# SAMA7D65D4GN8 register map
Vendor: Microchip Technology; Series: SAMA7D6; File version: 0
Registers are 32-bit, read-write, reset 0x0 unless marked. A register's access mark holds for its fields unless they carry their own. Offsets are from the block's base; [hi:lo] are bit positions; {n}, {i} and the like mark numbered series.

## SPDIFTX — Sony/Philips Digital Interface
Base 0xE2810000
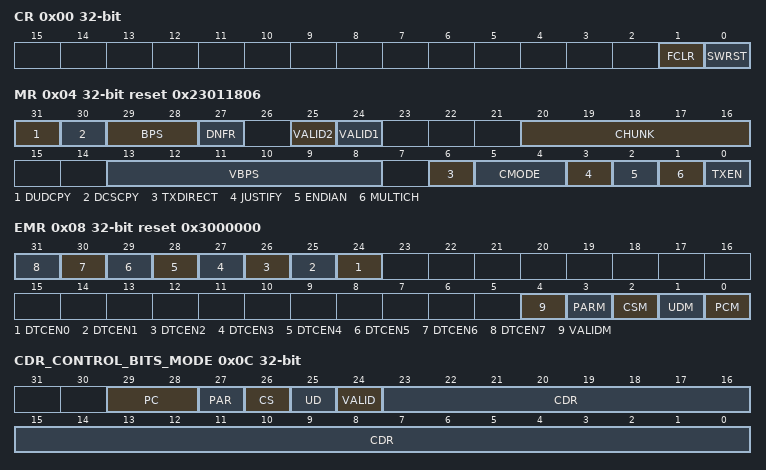
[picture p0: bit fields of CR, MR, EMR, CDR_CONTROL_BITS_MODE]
0x00 CR wo — SPDIF Transmitter Control Register
  [1] FCLR — FIFO clear
    0=No effect; 1=Empties Channel 1 and Channel 2 FIFOs
  [0] SWRST — Software Reset
    0=No effect; 1=Resets the SPDIFTX interface
0x04 MR reset 0x23011806 — SPDIF Transmitter Mode Register
  [31] DUDCPY — Disable User Data Copy
    0=Any data written in SPDDIFTX_CH1UDx registers is copied to SPDDIFTX_CH2UDx; 1=SPDDIFTX_CH1UDx and SPDDIFTX_CH2UDx are independent
  [30] DCSCPY — Disable Channel Status Copy
    0=Any data written in SPDDIFTX_CH1Sx registers is copied to SPDDIFTX_CH2Sx; 1=SPDDIFTX_CH1Sx and SPDDIFTX_CH2Sx are independent
  [29:28] BPS — Bytes Per Sample
    0=BYTE1 (SPDIFTX_CDR data holding operating mode is optimized for data size up to 8 bits.); 1=BYTE2 (SPDIFTX_CDR data holding operating mode is optimized for data size in range 9 to 16 bits.); 2=BYTE3 (SPDIFTX_CDR data holding operating mode is optimized for data size in range 17 to 24 bits.); 3=BYTE4 (SPDIFTX_CDR data holding operating mode is optimized for data size in range 25 to 32 bits.)
  [27] DNFR — Disable Null Frame on underrrun
    0=In case of Underrun (SPDIFTX_ISR.TXEMPTY flag is set and IP need a data) invalid frames are sent (validity bit at level '1'); 1=In case of Underrun (SPDIFTX_ISR.TXEMPTY flag is set and IP need a data) valid frames are sent
  [25] VALID2 — Validity Bit Channel 2
  [24] VALID1 — Validity Bit Channel 1
  [20:16] CHUNK — DMA Chunk Size
  [13:8] VBPS — Valid Bits Per Sample
  [6] TXDIRECT — Transmitter Direct Access Enable
    0=The SPDIFTX holding register must be written by software or DMA to transmit audio samples on the SPDIF line; 1=Asynchronous Sample Rate Converter (ASRC) can directly transfer the audio samples on the SPDIF line without software or DMA intervention
  [5:4] CMODE — Common Audio Register Transfer Mode (if BPS=2)
    0=CHANNEL_INDEX (SPDIFTX_CDR.CDR[25:24] indicates the channel on which the data CDR[23:0] will be transmitted (1 for channel 1, 2 for channel 2).Transmitted data are located on SPDIFTX_CDR.CDR[23:0].); 1=CHANNELS_TOGGLING (The data are stored alternately in the FIFO of channel 1 and channel 2. The first sent data after a software or hardware reset is stored in the FIFO of channel 1. Transmitted data are located on SPDIFTX_CDR.CDR[23:0].); 2=COMPACT_24BIT (This mode is optimized for 24-bit data compacted on 32-bit memory space. Transmitted data are located on SPDIFTX_CDR.CDR[31:0]. The 32 bits of SPDIFTX_CDR are used and contains one or more channel data.); 3=CONTROL_BITS (Control bits (preamble, validity, user data, channel status, parity) can be managed by writing SPDIFTX_CDR.CDR[31:24] depending on SPDIFTX_EMR configuration. The data are stored alternately in the FIFO of channel 1 and channel 2. The first data sent after a software or hardware reset is stored in the FIFO of channel 1. Transmitted data are located on SPDIFTX_CDR.CDR[23:0].)
  [3] JUSTIFY — Data Justification
    0=LSB (Least Significant Bit justification. The valid bits of the signal are aligned on the least-significant bits of the container.); 1=MSB (Most Significant Bit justification. The valid bits of the signal are aligned on the most-significant bits of the container.)
  [2] ENDIAN — Data Word Endian Mode
    0=LITTLE (Little-endian mode.); 1=BIG (Big-endian mode.)
  [1] MULTICH — Multichannel Transfer
    0=MONO (One channel is sent on channel 1 to SPDIFTX_TX and is copied on channel 2.); 1=DUAL (Two separate channels are sent to SPDIFTX_TX.)
  [0] TXEN — SPDIFTX Transmit Enable
    0=DISABLE (SPDIFTX transmission is disabled.); 1=ENABLE (SPDIFTX transmission is enabled.)
0x08 EMR reset 0x3000000 — SPDIF Transmitter Extended Mode Register
  [n+24] DTCEN{n} (n=0..7) — Direct Audio Transmit Channel {n} Enable
    0=The channel x from the direct audio stream is not transmitted on the SPDIF line; 1=The channel x from the direct audio stream is transmitted on the SPDIF line
  [4] VALIDM — Validity Bit Mode
    0=Validity bit is defined by SPDIFTX_MR.VALID1 and SPDIFTX_MR.VALID2 values; 1=Validity bit is defined by the SPDIFTX_CDR.VALID bit
  [3] PARM — Parity Mode
    0=Parity bit is automatically set by the SPDIFTX; 1=Parity bit sent is defined by SPDIFTX_CDR.PAR bit
  [2] CSM — Channel Status Mode
    0=Channel status is defined by SPDIFTX_CHxCSx registers; 1=Channel status is defined by SPDIFTX_CDR.CS bit
  [1] UDM — User Data Mode
    0=User data is defined by SPDIFTX_CHxUDx registers; 1=User data is defined by SPDIFTX_CDR.UD bit
  [0] PCM — Preamble Code Mode
    0=Preamble code is generated automatically by the SPDIFTX; 1=Preamble code is defined by SPDIFTX_CDR.PC field
0x0C CDR wo — SPDIF Transmitter Common Data Register
  [31:0] CDR — Common Data Register
0x0C CDR_CONTROL_BITS_MODE wo (alternate view of CDR) — SPDIF Transmitter Common Data Register
  [29:28] PC — Preamble Code
    0=PREAMBLE_B (Preamble 'B' will be sent.); 1=PREAMBLE_M (Preamble 'M' will be sent.); 2=PREAMBLE_W (Preamble 'W' will be sent.)
  [27] PAR — Parity
    0=Correct parity bit will be sent; 1=Wrong parity bit will be sent
  [26] CS — Channel Status
  [25] UD — User Data
  [24] VALID — Validity Bit
    0=Sample is valid for analog conversion; 1=Sample is not valid for analog conversion
  [23:0] CDR — Common Data Register
0x10 SR ro — SPDIF Transmitter Status Register
  [0] ENS — Enable Status
    0=SPDIF core is disabled; 1=SPDIF core is enabled
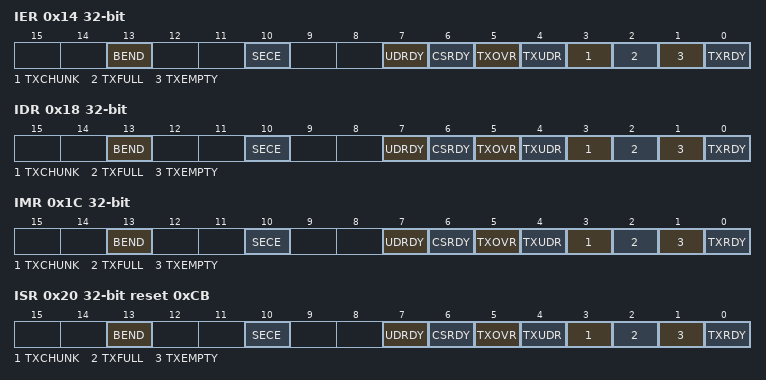
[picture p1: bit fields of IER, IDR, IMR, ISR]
0x14 IER wo — SPDIF Transmitter Interrupt Enable Register
  [13] BEND — Block End Interrupt Enable
  [10] SECE — Security Report Interrupt Enable
  [7] UDRDY — User Data Ready Interrupt Enable
  [6] CSRDY — Channel Status Ready Interrupt Enable
  [5] TXOVR — Transmit Over Flow Interrupt Enable
  [4] TXUDR — Transmit Under Flow Interrupt Enable
  [3] TXCHUNK — Transmit FIFO Chunk Size Empty Interrupt Enable
  [2] TXFULL — Transmit FIFO Full Interrupt Enable
  [1] TXEMPTY — Transmit FIFO Empty Interrupt Enable
  [0] TXRDY — Transmit Ready Interrupt Enable
0x18 IDR wo — SPDIF Transmitter Interrupt Disable Register
  [13] BEND — Block End Interrupt Disable
  [10] SECE — Security Report Interrupt Disable
  [7] UDRDY — User Data Ready Interrupt Disable
  [6] CSRDY — Channel Status Ready Interrupt Disable
  [5] TXOVR — Transmit Over Flow Interrupt Disable
  [4] TXUDR — Transmit Under Flow Interrupt Disable
  [3] TXCHUNK — Transmit FIFO Chunk Size Empty Interrupt Disable
  [2] TXFULL — Transmit FIFO Full Interrupt Disable
  [1] TXEMPTY — Transmit FIFO Empty Interrupt Disable
  [0] TXRDY — Transmit Ready Interrupt Disable
0x1C IMR ro — SPDIF Transmitter Interrupt Mask Register
  [13] BEND — Block End Interrupt Mask
  [10] SECE — Security Report Interrupt Mask
  [7] UDRDY — User Data Ready Interrupt Mask
  [6] CSRDY — Channel Status Ready Interrupt Mask
  [5] TXOVR — Transmit Over Flow Interrupt Mask
  [4] TXUDR — Transmit Under Flow Interrupt Mask
  [3] TXCHUNK — Transmit FIFO Chunk Size Empty Interrupt Mask
  [2] TXFULL — Transmit FIFO Full Interrupt Mask
  [1] TXEMPTY — Transmit FIFO Empty Interrupt Mask
  [0] TXRDY — Transmit Ready Interrupt Mask
0x20 ISR ro reset 0xCB — SPDIF Transmitter Interrupt Status Register
  [13] BEND — Block End Status (cleared on read)
    0=No Block End event occurred since last SPDIFTX_ISR read; 1=At least one Block End event occurred since last SPDIFTX_ISR read
  [10] SECE — Security Report Status (cleared on read)
  [7] UDRDY — User Data Ready Status (cleared writing SPDIFTX_CHxUDR0 register)
  [6] CSRDY — Channel Status Ready Status (cleared writing SPDIFTX_CHxSR0 register)
  [5] TXOVR — Transmit Over Flow Status (cleared on read)
  [4] TXUDR — Transmit Under Flow Status (cleared on read)
  [3] TXCHUNK — Transmit FIFO Chunk Size Empty Status (cleared by writing CHUNK data in SPDIFTX_CDR)
  [2] TXFULL — Transmit FIFO Full Status (cleared when data are sent or writing the SPDIFTX_CR.FCLR bit)
  [1] TXEMPTY — Transmit FIFO Empty Status (cleared by writing SPDIFTX_CDR register)
  [0] TXRDY — Transmit Ready Status (cleared when both channel 1 and 2 FIFOs are full)
0x24 SFI ro reset 0x17F — SPDIF Transmitter Subframe Index Register
  [9:0] SFI — Transmit Subframe Index
{0x50+4i} CH1UD[{i}] (i=0..5) — SPDIF Transmitter User Data 1 Register x
  [31:0] CHUD — Channel 1 User Data Word
{0x68+4i} CH2UD[{i}] (i=0..5) — SPDIF Transmitter User Data 2 Register x
  [31:0] CHUD — Channel 2 User Data Word
{0x80+4i} CH1S[{i}] (i=0..5) — SPDIF Transmitter Channel Status 1 Register x
  [31:0] CHS — Channel 1 Status Word
{0x98+4i} CH2S[{i}] (i=0..5) — SPDIF Transmitter Channel Status 2 Register x
  [31:0] CHS — Channel 2 Status Word
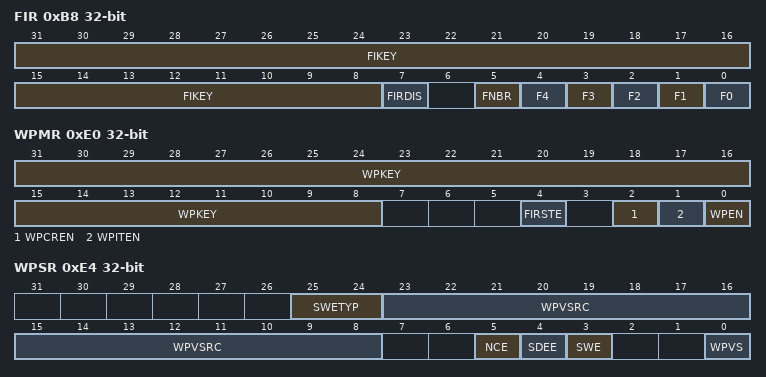
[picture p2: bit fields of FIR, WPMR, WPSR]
0xB8 FIR — SPDIF Transmitter Fault Injection Register
  [31:8] FIKEY — Fault Injection Key
    0x534649=PASSWD (Writing any other value in this field aborts the write operation. Always reads as 0.)
  [7] FIRDIS — Fault Injection Register Disable
    0=NO_EFFECT; 1=ACTIVE (Disables the fault injection until the next hardware reset. The command is valid only if the flags SPDIFTX_WPSR.SDEE=0 and SPDIFTX_WPSR.NCE=0 and the other bits are cleared (F0=F1=F2=F3=F4=0).)
  [5] FNBR — Fault Number
    0=SINGLE (One error is injected in the selected register.); 1=DOUBLE (Two errors are injected in the selected register.)
  [4] F4 — Single Fault for Write Protection Mode Register (SPDIFTX_WPMR)
    0=No effect; 1=Injects a single fault in the reinforced safety for the SPDIFTX_WPMR if 0x534649 ('SFI' in ASCII) is written in the FIKEY field at the same time. The flags SPDIFTX_ISR.SECE=1, SPDIFTX_WPSR.SDEE=1. If DUAL=1, the flag SPDIFTX_WPSR.NCE=1.
  [3] F3 — Single Fault for Channel Status Registers (SPDIFTX_CH1Sx/CH2Sx)
    0=No effect; 1=Injects a single fault in the reinforced safety for the SPDIFTX_CH1Sx/CH2Sx if 0x534649 ('SFI' in ASCII) is written in the FIKEY field at the same time. The flags SPDIFTX_ISR.SECE=1, SPDIFTX_WPSR.SDEE=1 and SPDIFTX_WPSR.NCE=1.
  [2] F2 — Single Fault for User Data Registers (SPDIFTX_CH1UDx/CH2UDx)
    0=No effect; 1=Injects a single fault in the reinforced safety for the SPDIFTX_CH1/2UDx if 0x534649 ('SFI' in ASCII) is written in the FIKEY field at the same time. The flags SPDIFTX_ISR.SECE=1 , SPDIFTX_WPSR.SDEE=1 and SPDIFTX_WPSR.NCE=1.
  [1] F1 — Single Fault for Interrupt Mask Register (SPDIFTX_IMR)
    0=No effect; 1=Injects a single fault in the reinforced safety for the SPDIFTX_IMR if 0x534649 ('SFI' in ASCII) is written in the FIKEY field at the same time. The flag SPDIFTX_ISR.SECE=1, SPDIFTX_WPSR.SDEE=1 and SPDIFTX_WPSR.NCE=1.
  [0] F0 — Single Fault for Mode Registers (SPDIFTX_MR and SPDIFTX_EMR)
    0=No effect; 1=Injects a single fault in the reinforced safety for the SPDIFTX_MR and SPDIFTX_EMR if 0x534649 ('SFI' in ASCII) is written in the FIKEY field at the same time. The flags SPDIFTX_ISR.SECE=1, SPDIFTX_WPSR.SDEE=1. If DUAL=1, the flag SPDIFTX_WPSR.NCE=1.
0xE0 WPMR — SPDIF Transmitter Write Protection Mode Register
  [31:8] WPKEY — Write Protection Key
    0x444946=PASSWD (Writing any other value in this field aborts the write operation of the WPEN bit. Always reads as 0.)
  [4] FIRSTE — First Error Report Enable
    0=The last write protection violation source is reported in SPDIFTX_WPSR.WPVSRC and the last software control error type is reported in SPDIFTX_WPSR.SWETYP. The SPDIFTX_ISR.SECE flag is set at the first error occurrence within a series.; 1=Only the first write protection violation source is reported in SPDIFTX_WPSR.WPVSRC and only the first software control error type is reported in SPDIFTX_WPSR.SWETYP. The SPDIFTX_ISR.SECE flag is set at the first error occurrence within a series.
  [2] WPCREN — Write Protection Control Register Enable
    0=Disables the write protection on the Control register if WPKEY corresponds to 0x444946; 1=Enables the write protection on the Control register if WPKEY corresponds to 0x444946
  [1] WPITEN — Write Protection Interrupt Enable
    0=Disables the write protection on Interrupt registers if WPKEY corresponds to 0x444946; 1=Enables the write protection on Interrupt registers if WPKEY corresponds to 0x444946
  [0] WPEN — Write Protection Enable
    0=Disables the write protection if WPKEY corresponds to 0x444946 (DIF in ASCII); 1=Enables the write protection if WPKEY corresponds to 0x444946 (DIF in ASCII)
0xE4 WPSR ro — SPDIF Transmitter Write Protection Status Register
  [25:24] SWETYP — Software Error Type (cleared on read)
    0=READ_WO (A write-only register has been read (warning).); 1=WRITE_RO (A write access has been performed on a read-only register (warning).); 2=UNDEF_RW (Access to an undefined address (warning).)
  [23:8] WPVSRC — Write Protection Violation Source
  [5] NCE — Non Corrected Error (cleared by reconfiguring the faulty registers or by clearing the error via SPDIFTX_FIR)
    0=A single error is detected (SDEE=1) or no error (SDEE=0); 1=A double error is detected in some configuration registers (SDEE=1)
  [4] SDEE — Single or Dual Event Error (cleared by reconfiguring the faulty registers or by clearing the error via SPDIFTX_FIR)
    0=No single or dual error detected; 1=Single or dual error detected in configuration registers. If a single error event occurred, the error is corrected (NCE=0).
  [3] SWE — Software Control Error (cleared on read)
    0=No software error has occurred since the last read of SPDIFTX_WPSR; 1=A software error has occurred since the last read of SPDIFTX_WPSR. The field SWETYP details the type of software error; the associated incorrect software access is reported in the field WPVSRC (if WPVS=0).
  [0] WPVS — Write Protection Violation Status (cleared on read)
    0=No write protection violation has occurred since the last read of the QSPI_WPSR; 1=A write protection violation has occurred since the last read of the QSPI_WPSR. If this violation is an unauthorized attempt to write a protected register, the associated violation is reported in the field WPVSRC.
